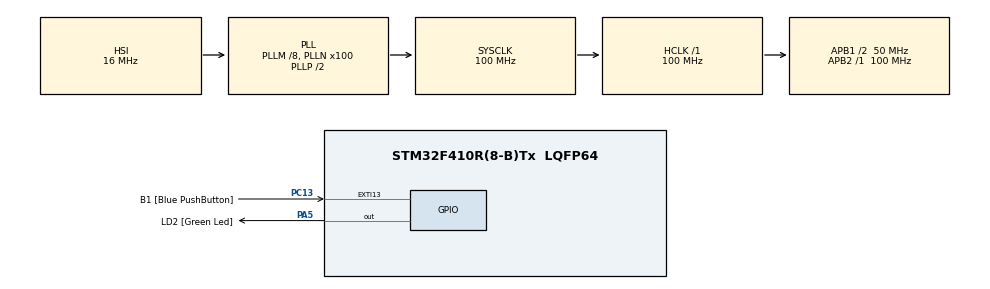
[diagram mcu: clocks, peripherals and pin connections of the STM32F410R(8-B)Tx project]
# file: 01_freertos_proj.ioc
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Mcu.Family=STM32F4
Mcu.Name=STM32F410R(8-B)Tx
Mcu.Package=LQFP64
NVIC.PriorityGroup=NVIC_PRIORITYGROUP_4
NVIC.TIM6_DAC_IRQn=true\:0\:0\:false\:false\:true\:false\:true\:true
NVIC.TimeBase=TIM6_DAC_IRQn
NVIC.TimeBaseIP=TIM6
PA13.GPIO_Label=TMS
PA13.Signal=SYS_JTMS-SWDIO
PA14.GPIO_Label=TCK
PA14.Signal=SYS_JTCK-SWCLK
PA2.GPIO_Label=USART_TX
PA2.GPIO_Mode=GPIO_MODE_AF_PP
PA2.GPIO_PuPd=GPIO_NOPULL
PA2.GPIO_Speed=GPIO_SPEED_FREQ_VERY_HIGH
PA2.Signal=USART2_TX
PA3.GPIO_Label=USART_RX
PA3.GPIO_Mode=GPIO_MODE_AF_PP
PA3.GPIO_PuPd=GPIO_NOPULL
PA3.GPIO_Speed=GPIO_SPEED_FREQ_VERY_HIGH
PA3.Signal=USART2_RX
PA5.GPIO_Label=LD2 [Green Led]
PA5.GPIO_ModeDefaultOutputPP=GPIO_MODE_OUTPUT_PP
PA5.GPIO_PuPd=GPIO_NOPULL
PA5.GPIO_Speed=GPIO_SPEED_FREQ_LOW
PA5.Signal=GPIO_Output
PB3.GPIO_Label=SWO
PB3.Signal=SYS_JTDO-SWO
PC13-ANTI_TAMP.GPIO_Label=B1 [Blue PushButton]
PC13-ANTI_TAMP.GPIO_ModeDefaultEXTI=GPIO_MODE_IT_FALLING
PC13-ANTI_TAMP.GPIO_PuPd=GPIO_NOPULL
PC13-ANTI_TAMP.Signal=GPXTI13
PC14-OSC32_IN.Signal=RCC_OSC32_IN
PC15-OSC32_OUT.Signal=RCC_OSC32_OUT
PH0\ -\ OSC_IN.Signal=RCC_OSC_IN
PH1\ -\ OSC_OUT.Signal=RCC_OSC_OUT
ProjectManager.HeapSize=0x200
ProjectManager.StackSize=0x400
ProjectManager.TargetToolchain=STM32CubeIDE
RCC.48MHZClocksFreq_Value=50000000
RCC.AHBFreq_Value=100000000
RCC.APB1CLKDivider=RCC_HCLK_DIV2
RCC.APB1Freq_Value=50000000
RCC.APB1TimFreq_Value=100000000
RCC.APB2Freq_Value=100000000
RCC.APB2TimFreq_Value=100000000
RCC.CortexFreq_Value=100000000
RCC.FLatency-AdvancedSettings=FLASH_LATENCY_3
RCC.HCLKFreq_Value=100000000
RCC.HSE_VALUE=8000000
RCC.HSI_VALUE=16000000
RCC.LSE_VALUE=32768
RCC.PLLM=8
RCC.PLLN=100
RCC.SYSCLKFreq_VALUE=100000000
RCC.SYSCLKSource=RCC_SYSCLKSOURCE_PLLCLK
RCC.VCOOutputFreq_Value=200000000
VP_SYS_VS_tim6.Mode=TIM6
board=NUCLEO-F410RB

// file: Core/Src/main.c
/* USER CODE BEGIN Header */
/**
  ******************************************************************************
  * @file           : main.c
  * @brief          : Main program body
  ******************************************************************************
  * @attention
  *
  * Copyright (c) 2026 STMicroelectronics.
  * All rights reserved.
  *
  * This software is licensed under terms that can be found in the LICENSE file
  * in the root directory of this software component.
  * If no LICENSE file comes with this software, it is provided AS-IS.
  *
  ******************************************************************************
  */
/* USER CODE END Header */
#include "main.h"
#include "gpio.h"

/* USER CODE BEGIN Includes */
#include <stdio.h>
#include <stdint.h>
#include "FreeRTOS.h"
#include "task.h"
#include "SEGGER_SYSVIEW.h"
#include "SEGGER_RTT.h"
#include "HIF_UART.h"
/* USER CODE END Includes */

/* USER CODE BEGIN PD */
#define DWT_CTRL	(*(volatile uint32_t*)0xE0001000)

#define _SERVER_HELLO_SIZE        (4)
#define _TARGET_HELLO_SIZE        (4)
/* USER CODE END PD */

void SystemClock_Config(void);
/* USER CODE BEGIN PFP */
static void task1_handler(void* params);
static void task2_handler(void* params);
/* USER CODE END PFP */

/* USER CODE BEGIN 0 */
__attribute__((section(".heap")))
uint8_t ucHeap[configTOTAL_HEAP_SIZE];

static const U8 _abHelloMsg[_TARGET_HELLO_SIZE] = { 'S', 'V', (SEGGER_SYSVIEW_VERSION / 10000), (SEGGER_SYSVIEW_VERSION / 1000) % 10 };  // "Hello" message expected by SysView: [ 'S', 'V', <PROTOCOL_MAJOR>, <PROTOCOL_MINOR> ]

static struct {
  U8         NumBytesHelloRcvd;
  U8         NumBytesHelloSent;
  int        ChannelID;
} _SVInfo;

static void _StartSysView(void) {
  int r;
  r = SEGGER_SYSVIEW_IsStarted();
  if (r == 0) {
    SEGGER_SYSVIEW_Start();
  }
}
/*********************************************************************
*
*       _cbOnRx()
*
*  Function description
*    This function is called when the UART receives data.
*/
static void _cbOnRx(U8 Data) {
  if (_SVInfo.NumBytesHelloRcvd < _SERVER_HELLO_SIZE) {  // Not all bytes of <Hello> message received by SysView yet?
    _SVInfo.NumBytesHelloRcvd++;
    if (_SVInfo.NumBytesHelloRcvd == _SERVER_HELLO_SIZE) {
      HIF_UART_EnableTXEInterrupt();  // Reply before trace events exist.
    }
    goto Done;
  }
  _StartSysView();
  SEGGER_RTT_WriteDownBuffer(_SVInfo.ChannelID, &Data, 1);  // Write data into corresponding RTT buffer for application to read and handle accordingly
Done:
  return;
}

/*********************************************************************
*
*       _cbOnTx()
*
*  Function description
*    This function is called when the UART should transmit data.
*/
static int _cbOnTx(U8* pChar) {
  int r;

  if (_SVInfo.NumBytesHelloSent < _TARGET_HELLO_SIZE) {  // Not all bytes of <Hello> message sent to SysView yet?
    *pChar = _abHelloMsg[_SVInfo.NumBytesHelloSent];
    _SVInfo.NumBytesHelloSent++;
    r = 1;
    goto Done;
  }
  r = SEGGER_RTT_ReadUpBufferNoLock(_SVInfo.ChannelID, pChar, 1);
  if (r < 0) {  // Failed to read from up buffer?
    r = 0;
  }
Done:
  return r;
}
/* USER CODE END 0 */

int main(void)
{

  /* USER CODE BEGIN 1 */
	TaskHandle_t task1_handle;
	TaskHandle_t task2_handle;

	BaseType_t status;
  /* USER CODE END 1 */

  /* MCU Configuration--------------------------------------------------------*/

  /* Reset of all peripherals, Initializes the Flash interface and the Systick. */
  HAL_Init();

  /* Configure the system clock */
  SystemClock_Config();

  /* Initialize all configured peripherals */
  MX_GPIO_Init();
  /* USER CODE BEGIN 2 */
  CoreDebug->DEMCR |= CoreDebug_DEMCR_TRCENA_Msk; // Enable Trace
  DWT->CYCCNT = 0;                                // Reset the cycle counter
  DWT->CTRL |= DWT_CTRL_CYCCNTENA_Msk;            // Enable cycle counter

  SEGGER_SYSVIEW_Conf();  // Allocate RTT buffers before enabling UART callbacks.
  _SVInfo.ChannelID = SEGGER_SYSVIEW_GetChannelID();
  HIF_UART_Init(400 * 1000, _cbOnTx, _cbOnRx);

  status = xTaskCreate(task1_handler,"Task-1",200,"hello world task 1",2,&task1_handle);

  configASSERT(status == pdPASS);

  status = xTaskCreate(task2_handler,"Task-2",200,"hello world task 2",2,&task2_handle);

  configASSERT(status == pdPASS);

  vTaskStartScheduler();
  /* USER CODE END 2 */

  /* Infinite loop */
  while (1)
  {

  }
}

void SystemClock_Config(void)
{
  RCC_OscInitTypeDef RCC_OscInitStruct = {0};
  RCC_ClkInitTypeDef RCC_ClkInitStruct = {0};

  /** Configure the main internal regulator output voltage
  */
  __HAL_RCC_PWR_CLK_ENABLE();
  __HAL_PWR_VOLTAGESCALING_CONFIG(PWR_REGULATOR_VOLTAGE_SCALE1);

  /** Initializes the RCC Oscillators according to the specified parameters
  * in the RCC_OscInitTypeDef structure.
  */
  RCC_OscInitStruct.OscillatorType = RCC_OSCILLATORTYPE_HSI;
  RCC_OscInitStruct.HSIState = RCC_HSI_ON;
  RCC_OscInitStruct.HSICalibrationValue = RCC_HSICALIBRATION_DEFAULT;
  RCC_OscInitStruct.PLL.PLLState = RCC_PLL_ON;
  RCC_OscInitStruct.PLL.PLLSource = RCC_PLLSOURCE_HSI;
  RCC_OscInitStruct.PLL.PLLM = 8;
  RCC_OscInitStruct.PLL.PLLN = 100;
  RCC_OscInitStruct.PLL.PLLP = RCC_PLLP_DIV2;
  RCC_OscInitStruct.PLL.PLLQ = 4;
  RCC_OscInitStruct.PLL.PLLR = 2;
  if (HAL_RCC_OscConfig(&RCC_OscInitStruct) != HAL_OK)
  {
    Error_Handler();
  }

  /** Initializes the CPU, AHB and APB buses clocks
  */
  RCC_ClkInitStruct.ClockType = RCC_CLOCKTYPE_HCLK|RCC_CLOCKTYPE_SYSCLK
                              |RCC_CLOCKTYPE_PCLK1|RCC_CLOCKTYPE_PCLK2;
  RCC_ClkInitStruct.SYSCLKSource = RCC_SYSCLKSOURCE_PLLCLK;
  RCC_ClkInitStruct.AHBCLKDivider = RCC_SYSCLK_DIV1;
  RCC_ClkInitStruct.APB1CLKDivider = RCC_HCLK_DIV2;
  RCC_ClkInitStruct.APB2CLKDivider = RCC_HCLK_DIV1;

  if (HAL_RCC_ClockConfig(&RCC_ClkInitStruct, FLASH_LATENCY_3) != HAL_OK)
  {
    Error_Handler();
  }
}

/* USER CODE BEGIN 4 */
static void task1_handler(void* params){
	while(1){
		printf("%s\n",(char*)params);
	}

}

static void task2_handler(void* params){
	while(1){
		printf("%s\n",(char*)params);
	}
}
/* USER CODE END 4 */

void HAL_TIM_PeriodElapsedCallback(TIM_HandleTypeDef *htim)
{
  if (htim->Instance == TIM6)
  {
    HAL_IncTick();
  }
}

void Error_Handler(void)
{
  __disable_irq();
  while (1)
  {
  }
}
